# slm32x030 register map
Vendor: Keil; File version: 1.0.1
CPU: CM0 r2p1, little endian, no MPU, no FPU, 4 interrupt priority bits
Registers are 32-bit, read-write, reset 0x0 unless marked. A register's access mark holds for its fields unless they carry their own. Offsets are from the block's base; [hi:lo] are bit positions; {n}, {i} and the like mark numbered series; 'fields as' and 'values as' point back to an identical list.

## ADC — analog to digital(ADC)
Base 0x40012400
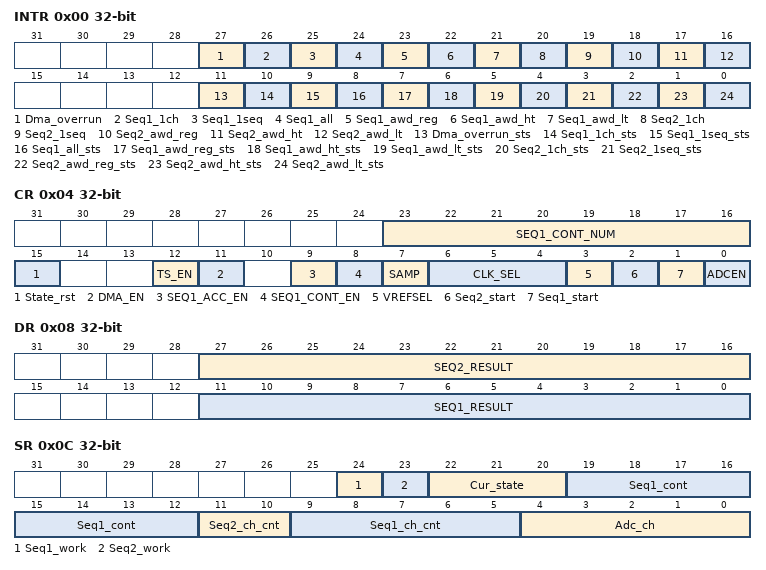
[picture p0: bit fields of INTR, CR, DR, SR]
0x00 INTR — ADC_INTR
  [27] Dma_overrun — Later Add Description
  [26] Seq1_1ch — Later Add Description
  [25] Seq1_1seq — Later Add Description
  [24] Seq1_all — Later Add Description
  [23] Seq1_awd_reg — Later Add Description
  [22] Seq1_awd_ht — Later Add Description
  [21] Seq1_awd_lt — Later Add Description
  [20] Seq2_1ch — Later Add Description
  [19] Seq2_1seq — Later Add Description
  [18] Seq2_awd_reg — Later Add Description
  [17] Seq2_awd_ht — Later Add Description
  [16] Seq2_awd_lt — Later Add Description
  [11] Dma_overrun_sts — Later Add Description
  [10] Seq1_1ch_sts — Later Add Description
  [9] Seq1_1seq_sts — Later Add Description
  [8] Seq1_all_sts — Later Add Description
  [7] Seq1_awd_reg_sts — Later Add Description
  [6] Seq1_awd_ht_sts — Later Add Description
  [5] Seq1_awd_lt_sts — Later Add Description
  [4] Seq2_1ch_sts — Later Add Description
  [3] Seq2_1seq_sts — Later Add Description
  [2] Seq2_awd_reg_sts — Later Add Description
  [1] Seq2_awd_ht_sts — Later Add Description
  [0] Seq2_awd_lt_sts — Later Add Description
0x04 CR — ADC_CR
  [23:16] SEQ1_CONT_NUM — Later Add Description
  [15] State_rst — Later Add Description
  [12] TS_EN — Later Add Description
  [11] DMA_EN — Later Add Description
  [9] SEQ1_ACC_EN — Later Add Description
  [8] SEQ1_CONT_EN — Later Add Description
  [7] SAMP — Later Add Description
  [6:4] CLK_SEL — Later Add Description
  [3] VREFSEL — Later Add Description
  [2] Seq2_start — Later Add Description
  [1] Seq1_start — Later Add Description
  [0] ADCEN — Later Add Description
0x08 DR — ADC_DR
  [27:16] SEQ2_RESULT — Later Add Description
  [11:0] SEQ1_RESULT — Later Add Description
0x0C SR — ADC_SR
  [24] Seq1_work — Later Add Description
  [23] Seq2_work — Later Add Description
  [22:20] Cur_state — Later Add Description
  [19:12] Seq1_cont — Later Add Description
  [11:10] Seq2_ch_cnt — Later Add Description
  [9:5] Seq1_ch_cnt — Later Add Description
  [4:0] Adc_ch — Later Add Description
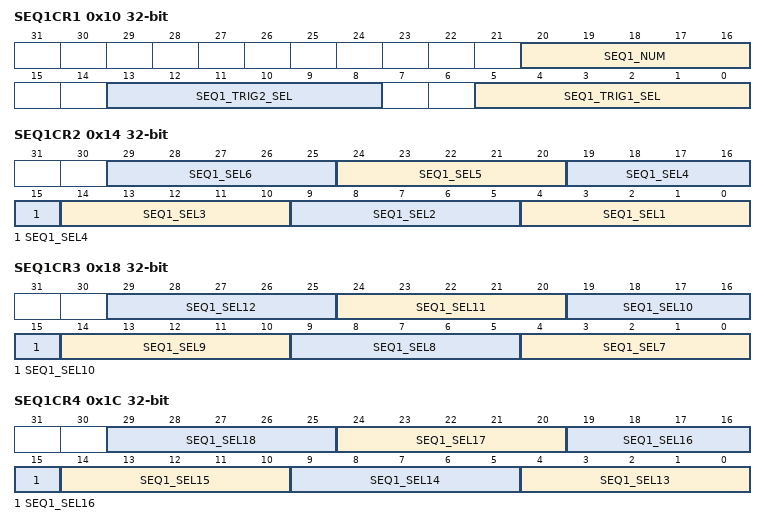
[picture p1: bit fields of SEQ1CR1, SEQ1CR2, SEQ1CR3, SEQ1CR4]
0x10 SEQ1CR1 — ADC_SEQ1CR1
  [20:16] SEQ1_NUM — Later Add Description
  [13:8] SEQ1_TRIG2_SEL — Later Add Description
  [5:0] SEQ1_TRIG1_SEL — Later Add Description
0x14 SEQ1CR2 — ADC_SEQ1CR2
  [5n-1:5n-5] SEQ1_SEL{n} (n=1..6) — Later Add Description
0x18 SEQ1CR3 — ADC_SEQ1CR3
  [5n-31:5n-35] SEQ1_SEL{n} (n=7..12) — Later Add Description
0x1C SEQ1CR4 — ADC_SEQ1CR4
  [5n-61:5n-65] SEQ1_SEL{n} (n=13..18) — Later Add Description
0x20 SEQ1SR1 — ADC_SEQ1SR1
  [11:0] SEQ1_RESULT — Later Add Description
{0x1C+4i} SEQ1SR{i} (i=2..18) — ADC_SEQ1SR{i}
  [10:0] SEQ1_RESULT — Later Add Description
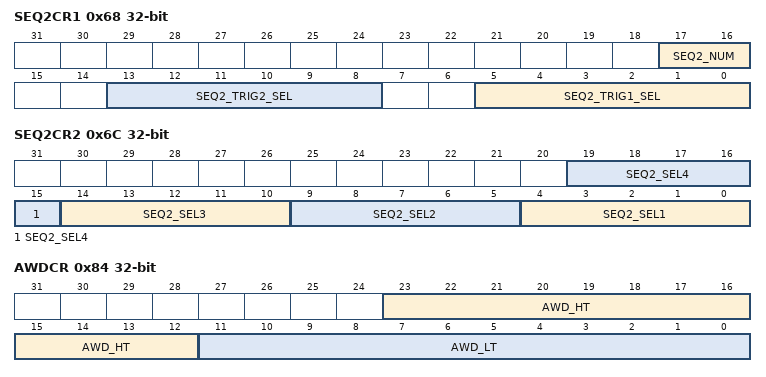
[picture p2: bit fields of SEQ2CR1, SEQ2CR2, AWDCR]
0x68 SEQ2CR1 — ADC_SEQ2CR1
  [17:16] SEQ2_NUM — Later Add Description
  [13:8] SEQ2_TRIG2_SEL — Later Add Description
  [5:0] SEQ2_TRIG1_SEL — Later Add Description
0x6C SEQ2CR2 — ADC_SEQ2CR2
  [5n-1:5n-5] SEQ2_SEL{n} (n=1..4) — Later Add Description
{0x6C+4i} SEQ2SR{i} (i=1..4) — ADC_SEQ2SR{i}
  [11:0] SEQ2_RESULT — Later Add Description
0x80 ACCR — ADC_ACCR
  [19:0] ACC — Later Add Description
0x84 AWDCR — ADC_AWDCR
  [23:12] AWD_HT — Later Add Description
  [11:0] AWD_LT — Later Add Description

## DMA — DMA(DMA)
Base 0x40020000
0x00 INTSTA — DMA_INTSTA
  [5:0] INT_STA — Later Add Description
0x04 INTTCSTA — DMA_INTTCSTA
  [5:0] INT_TC_STA — Later Add Description
0x08 INCTTCCLR — DMA_INCTTCCLR
  [5:0] INT_TC_CLR — Later Add Description
0x0C INTERRSTA — DMA_INTERRSTA
  [5:0] INT_ERR_STA — Later Add Description
0x10 INTERRCLR — DMA_INTERRCLR
  [5:0] INT_ERR_CLR — Later Add Description
0x14 RAWINTTCSTA — DMA_RAWINTTCSTA
  [5:0] INT_TC_RAW_STA — Later Add Description
0x18 RAWINTERRSTA — DMA_RAWINTERRSTA
  [5:0] INT_ERR_RAW_STA — Later Add Description
0x1C ENBLDCHNSTA — DMA_ENBLDCHNSTA
  [5:0] CH_WORK — Later Add Description
0x24 SOFTSREQ — DMA_SOFTSREQ
  [5:0] SOFT_SREQ — Later Add Description
0x28 OVSTA — DMA_OVSTA
  [5:0] OVER_RUN_STA — Later Add Description
0x2C OVCLR — DMA_OVCLR
  [5:0] OVER_RUN_CLR — Later Add Description
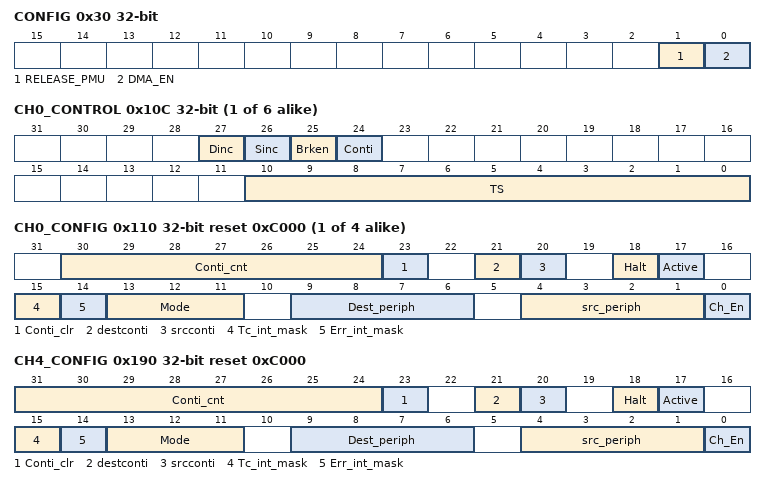
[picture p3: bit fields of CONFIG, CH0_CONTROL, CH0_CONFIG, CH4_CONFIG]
0x30 CONFIG — DMA_CONFIG
  [1] RELEASE_PMU — Later Add Description
  [0] DMA_EN — Later Add Description
0x34 PERIPH0_SEL — DMA_PERIPH0_SEL
  [4:0] PERIPH_SEL0 — Later Add Description
{0x34+4i} PERIPH{i}_SEL (i=1..5) — DMA_PERIPH{i}_SEL
  [5:0] PERIPH_SEL{i} — Later Add Description
{0x100+0x20*i} CH{i}_SRCADDR (i=0..5) — DMA_CH{i}_SRCADDR
  [30:0] SRC_ADDR — Later Add Description
0x104 CH0_DESTADDR — DMA_CH0_DESTADDR
  [31:0] DEST_ADDR — Later Add Description
{0x10C+0x20*i} CH{i}_CONTROL (i=0..5) — DMA_CH{i}_CONTROL
  [27] Dinc — Later Add Description
  [26] Sinc — Later Add Description
  [25] Brken — Later Add Description
  [24] Conti — Later Add Description
  [10:0] TS — Later Add Description
{0x110+0x20*i} CH{i}_CONFIG reset 0xC000 (i=0..3) — DMA_CH{i}_CONFIG
  [30:24] Conti_cnt — Later Add Description
  [23] Conti_clr — Later Add Description
  [21] destconti — Later Add Description
  [20] srcconti — Later Add Description
  [18] Halt — Later Add Description
  [17] Active — Later Add Description
  [15] Tc_int_mask — Later Add Description
  [14] Err_int_mask — Later Add Description
  [13:11] Mode — Later Add Description
  [9:6] Dest_periph — Later Add Description
  [4:1] src_periph — Later Add Description
  [0] Ch_En — Later Add Description
{0x104+0x20*i} CH{i}_DESTADDR (i=1..5) — DMA_CH{i}_DESTADDR
  [30:0] DEST_ADDR — Later Add Description
0x190 CH4_CONFIG reset 0xC000 — DMA_CH4_CONFIG
  [31:24] Conti_cnt — Later Add Description
  [23] Conti_clr — Later Add Description
  [21] destconti — Later Add Description
  [20] srcconti — Later Add Description
  [18] Halt — Later Add Description
  [17] Active — Later Add Description
  [15] Tc_int_mask — Later Add Description
  [14] Err_int_mask — Later Add Description
  [13:11] Mode — Later Add Description
  [9:6] Dest_periph — Later Add Description
  [4:1] src_periph — Later Add Description
  [0] Ch_En — Later Add Description
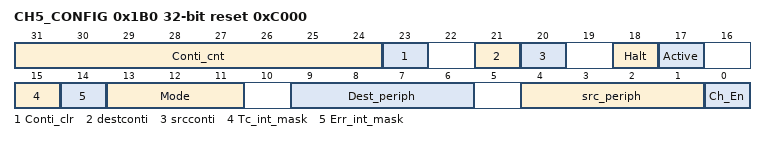
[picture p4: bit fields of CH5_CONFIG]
0x1B0 CH5_CONFIG reset 0xC000 — DMA_CH5_CONFIG
  fields as CH4_CONFIG
